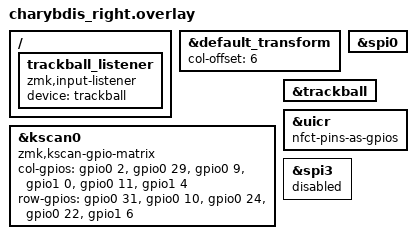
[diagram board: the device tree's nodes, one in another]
#include "charybdis.dtsi"
#include "charybdis_pmw3610.dtsi"

// The matrix transform is 6 columns over because the left half is 6 columns wide.
&default_transform {
	col-offset = <6>;
};

&kscan0 {
	compatible = "zmk,kscan-gpio-matrix";
	
	col-gpios
		= <&gpio0 2 (GPIO_ACTIVE_HIGH | GPIO_PULL_DOWN)>
		, <&gpio0 29 (GPIO_ACTIVE_HIGH | GPIO_PULL_DOWN)>
		, <&gpio0 9 (GPIO_ACTIVE_HIGH | GPIO_PULL_DOWN)>
		, <&gpio1 0  (GPIO_ACTIVE_HIGH | GPIO_PULL_DOWN)>
		, <&gpio0 11 (GPIO_ACTIVE_HIGH | GPIO_PULL_DOWN)>
		, <&gpio1 4  (GPIO_ACTIVE_HIGH | GPIO_PULL_DOWN)>
		;

	row-gpios
    = <&gpio0 31 GPIO_ACTIVE_HIGH>
    , <&gpio0 10 GPIO_ACTIVE_HIGH>  /* row 2 (Y U I O P) is wired to P0.10 on this half */
    , <&gpio0 24 GPIO_ACTIVE_HIGH>
	  , <&gpio0 22 GPIO_ACTIVE_HIGH>
    , <&gpio1 6  GPIO_ACTIVE_HIGH>
    ;
};

&spi0 {
    status = "okay";
};

&trackball {
    status = "okay";
};

// https://github.com/badjeff/zmk-pmw3610-driver
/ {
  trackball_listener {
    compatible = "zmk,input-listener";
    device = <&trackball>;
  };
};

/* P0.10 is an NFC pin on the nRF52840: switch the NFC pins to plain GPIOs so row 2 can use it,
   and release P0.10 from the (unused) RGB underglow SPI. */
&uicr {
    nfct-pins-as-gpios;
};

&spi3 {
    status = "disabled";
};
